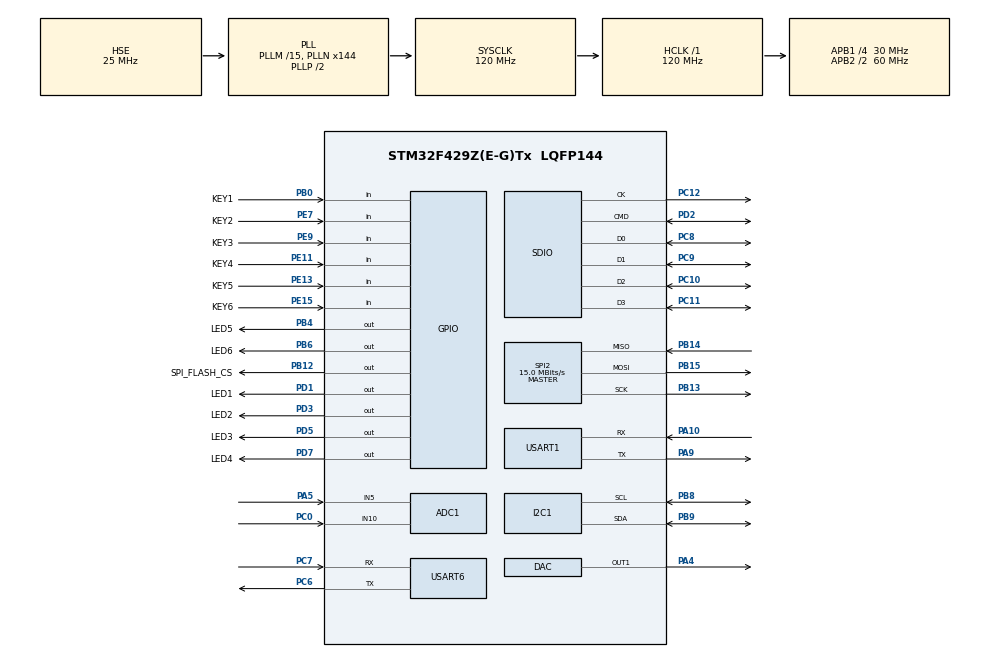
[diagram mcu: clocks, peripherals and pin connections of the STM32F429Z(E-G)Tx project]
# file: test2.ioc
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ADC1.Channel-0\#ChannelRegularConversion=ADC_CHANNEL_10
ADC1.Channel-1\#ChannelRegularConversion=ADC_CHANNEL_5
ADC1.ContinuousConvMode=DISABLE
ADC1.DMAContinuousRequests=DISABLE
ADC1.ExternalTrigConv=ADC_EXTERNALTRIGCONV_T3_TRGO
ADC1.NbrOfConversion=2
ADC1.NbrOfConversionFlag=1
ADC1.Rank-0\#ChannelRegularConversion=1
ADC1.Rank-1\#ChannelRegularConversion=2
ADC1.SamplingTime-0\#ChannelRegularConversion=ADC_SAMPLETIME_3CYCLES
ADC1.SamplingTime-1\#ChannelRegularConversion=ADC_SAMPLETIME_3CYCLES
ADC1.ScanConvMode=ENABLE
ADC1.master=1
DAC.DAC_Trigger=DAC_TRIGGER_T6_TRGO
Dma.ADC1.1.Direction=DMA_PERIPH_TO_MEMORY
Dma.ADC1.1.FIFOMode=DMA_FIFOMODE_DISABLE
Dma.ADC1.1.Instance=DMA2_Stream0
Dma.ADC1.1.MemDataAlignment=DMA_MDATAALIGN_WORD
Dma.ADC1.1.MemInc=DMA_MINC_ENABLE
Dma.ADC1.1.Mode=DMA_NORMAL
Dma.ADC1.1.PeriphDataAlignment=DMA_PDATAALIGN_WORD
Dma.ADC1.1.PeriphInc=DMA_PINC_DISABLE
Dma.ADC1.1.Priority=DMA_PRIORITY_LOW
Dma.DAC1.2.Direction=DMA_MEMORY_TO_PERIPH
Dma.DAC1.2.FIFOMode=DMA_FIFOMODE_DISABLE
Dma.DAC1.2.Instance=DMA1_Stream5
Dma.DAC1.2.MemDataAlignment=DMA_MDATAALIGN_HALFWORD
Dma.DAC1.2.MemInc=DMA_MINC_ENABLE
Dma.DAC1.2.Mode=DMA_CIRCULAR
Dma.DAC1.2.PeriphDataAlignment=DMA_PDATAALIGN_HALFWORD
Dma.DAC1.2.PeriphInc=DMA_PINC_DISABLE
Dma.DAC1.2.Priority=DMA_PRIORITY_LOW
Dma.Request0=USART1_RX
Dma.Request1=ADC1
Dma.Request2=DAC1
Dma.Request3=USART6_RX
Dma.USART1_RX.0.Direction=DMA_PERIPH_TO_MEMORY
Dma.USART1_RX.0.FIFOMode=DMA_FIFOMODE_DISABLE
Dma.USART1_RX.0.Instance=DMA2_Stream2
Dma.USART1_RX.0.MemDataAlignment=DMA_MDATAALIGN_BYTE
Dma.USART1_RX.0.MemInc=DMA_MINC_ENABLE
Dma.USART1_RX.0.Mode=DMA_NORMAL
Dma.USART1_RX.0.PeriphDataAlignment=DMA_PDATAALIGN_BYTE
Dma.USART1_RX.0.PeriphInc=DMA_PINC_DISABLE
Dma.USART1_RX.0.Priority=DMA_PRIORITY_HIGH
Dma.USART6_RX.3.Direction=DMA_PERIPH_TO_MEMORY
Dma.USART6_RX.3.FIFOMode=DMA_FIFOMODE_DISABLE
Dma.USART6_RX.3.Instance=DMA2_Stream1
Dma.USART6_RX.3.MemDataAlignment=DMA_MDATAALIGN_BYTE
Dma.USART6_RX.3.MemInc=DMA_MINC_ENABLE
Dma.USART6_RX.3.Mode=DMA_NORMAL
Dma.USART6_RX.3.PeriphDataAlignment=DMA_PDATAALIGN_BYTE
Dma.USART6_RX.3.PeriphInc=DMA_PINC_DISABLE
Dma.USART6_RX.3.Priority=DMA_PRIORITY_LOW
FATFS.USE_DMA_CODE_SD=0
FATFS._CODE_PAGE=936
FATFS._USE_LFN=3
I2C1.I2C_Mode=I2C_Fast
Mcu.Family=STM32F4
Mcu.Name=STM32F429Z(E-G)Tx
Mcu.Package=LQFP144
NVIC.ADC_IRQn=true\:0\:0\:true\:false\:true\:true\:true\:true
NVIC.DMA1_Stream5_IRQn=true\:0\:0\:true\:false\:true\:false\:true\:true
NVIC.DMA2_Stream0_IRQn=true\:0\:0\:true\:false\:true\:false\:true\:true
NVIC.DMA2_Stream1_IRQn=true\:0\:0\:false\:false\:true\:false\:true\:true
NVIC.DMA2_Stream2_IRQn=true\:0\:0\:false\:false\:true\:false\:true\:true
NVIC.PriorityGroup=NVIC_PRIORITYGROUP_2
NVIC.TIM8_UP_TIM13_IRQn=true\:0\:0\:false\:false\:true\:true\:true\:true
NVIC.USART1_IRQn=true\:0\:0\:false\:false\:true\:true\:true\:true
NVIC.USART6_IRQn=true\:0\:0\:false\:false\:true\:true\:true\:true
PA10.Mode=Asynchronous
PA10.Signal=USART1_RX
PA13.Mode=Serial_Wire
PA13.Signal=SYS_JTMS-SWDIO
PA14.Mode=Serial_Wire
PA14.Signal=SYS_JTCK-SWCLK
PA4.Signal=COMP_DAC1_group
PA5.Signal=ADCx_IN5
PA9.Mode=Asynchronous
PA9.Signal=USART1_TX
PB0.GPIO_Label=KEY1
PB0.GPIO_PuPd=GPIO_PULLUP
PB0.Signal=GPIO_Input
PB12.GPIO_Label=SPI_FLASH_CS
PB12.GPIO_Speed=GPIO_SPEED_FREQ_HIGH
PB12.PinState=GPIO_PIN_SET
PB12.Signal=GPIO_Output
PB13.Mode=Full_Duplex_Master
PB13.Signal=SPI2_SCK
PB14.Mode=Full_Duplex_Master
PB14.Signal=SPI2_MISO
PB15.Mode=Full_Duplex_Master
PB15.Signal=SPI2_MOSI
PB4.GPIO_Label=LED5
PB4.GPIO_PuPd=GPIO_PULLDOWN
PB4.Signal=GPIO_Output
PB6.GPIO_Label=LED6
PB6.GPIO_PuPd=GPIO_PULLDOWN
PB6.Signal=GPIO_Output
PB8.Mode=I2C
PB8.Signal=I2C1_SCL
PB9.Mode=I2C
PB9.Signal=I2C1_SDA
PC0.Signal=ADCx_IN10
PC10.Mode=SD_4_bits_Wide_bus
PC10.Signal=SDIO_D2
PC11.Mode=SD_4_bits_Wide_bus
PC11.Signal=SDIO_D3
PC12.Mode=SD_4_bits_Wide_bus
PC12.Signal=SDIO_CK
PC14/OSC32_IN.Mode=LSE-External-Oscillator
PC14/OSC32_IN.Signal=RCC_OSC32_IN
PC15/OSC32_OUT.Mode=LSE-External-Oscillator
PC15/OSC32_OUT.Signal=RCC_OSC32_OUT
PC6.Mode=Asynchronous
PC6.Signal=USART6_TX
PC7.Mode=Asynchronous
PC7.Signal=USART6_RX
PC8.Mode=SD_4_bits_Wide_bus
PC8.Signal=SDIO_D0
PC9.Mode=SD_4_bits_Wide_bus
PC9.Signal=SDIO_D1
PD1.GPIO_Label=LED1
PD1.GPIO_PuPd=GPIO_PULLDOWN
PD1.Signal=GPIO_Output
PD2.Mode=SD_4_bits_Wide_bus
PD2.Signal=SDIO_CMD
PD3.GPIO_Label=LED2
PD3.GPIO_PuPd=GPIO_PULLDOWN
PD3.Signal=GPIO_Output
PD5.GPIO_Label=LED3
PD5.GPIO_PuPd=GPIO_PULLDOWN
PD5.Signal=GPIO_Output
PD7.GPIO_Label=LED4
PD7.GPIO_PuPd=GPIO_PULLDOWN
PD7.Signal=GPIO_Output
PE11.GPIO_Label=KEY4
PE11.GPIO_PuPd=GPIO_PULLUP
PE11.Signal=GPIO_Input
PE13.GPIO_Label=KEY5
PE13.GPIO_PuPd=GPIO_PULLUP
PE13.Signal=GPIO_Input
PE15.GPIO_Label=KEY6
PE15.GPIO_PuPd=GPIO_PULLUP
PE15.Signal=GPIO_Input
PE7.GPIO_Label=KEY2
PE7.GPIO_PuPd=GPIO_PULLUP
PE7.Signal=GPIO_Input
PE9.GPIO_Label=KEY3
PE9.GPIO_PuPd=GPIO_PULLUP
PE9.Signal=GPIO_Input
PH0/OSC_IN.Mode=HSE-External-Oscillator
PH0/OSC_IN.Signal=RCC_OSC_IN
PH1/OSC_OUT.Mode=HSE-External-Oscillator
PH1/OSC_OUT.Signal=RCC_OSC_OUT
ProjectManager.HeapSize=0x200
ProjectManager.StackSize=0x400
ProjectManager.TargetToolchain=MDK-ARM V5.32
RCC.48MHZClocksFreq_Value=48000000
RCC.AHBFreq_Value=120000000
RCC.APB1CLKDivider=RCC_HCLK_DIV4
RCC.APB1Freq_Value=30000000
RCC.APB1TimFreq_Value=60000000
RCC.APB2CLKDivider=RCC_HCLK_DIV2
RCC.APB2Freq_Value=60000000
RCC.APB2TimFreq_Value=120000000
RCC.CortexFreq_Value=120000000
RCC.HCLKFreq_Value=120000000
RCC.HSE_VALUE=25000000
RCC.HSI_VALUE=16000000
RCC.PLLM=15
RCC.PLLN=144
RCC.PLLQ=5
RCC.PLLSourceVirtual=RCC_PLLSOURCE_HSE
RCC.SYSCLKFreq_VALUE=120000000
RCC.SYSCLKSource=RCC_SYSCLKSOURCE_PLLCLK
RCC.VCOOutputFreq_Value=240000000
SDIO.ClockDiv=6
SH.ADCx_IN10.0=ADC1_IN10,IN10
SH.ADCx_IN5.0=ADC1_IN5,IN5
SH.COMP_DAC1_group.0=DAC_OUT1,DAC_OUT1
SPI2.CLKPhase=SPI_PHASE_2EDGE
SPI2.CLKPolarity=SPI_POLARITY_HIGH
SPI2.CalculateBaudRate=15.0 MBits/s
SPI2.Direction=SPI_DIRECTION_2LINES
SPI2.Mode=SPI_MODE_MASTER
SPI2.VirtualType=VM_MASTER
STMicroelectronics.X-CUBE-ALGOBUILD.1.3.0.LibraryCcDSPOoLibraryJjDSPOoLibrary=true
TIM13.AutoReloadPreload=TIM_AUTORELOAD_PRELOAD_ENABLE
TIM13.Period=10000-1
TIM13.Prescaler=90-1
TIM3.AutoReloadPreload=TIM_AUTORELOAD_PRELOAD_ENABLE
TIM3.Period=100-1
TIM3.Prescaler=180-1
TIM3.TIM_MasterOutputTrigger=TIM_TRGO_UPDATE
TIM6.Period=100-1
TIM6.Prescaler=180-1
TIM6.TIM_MasterOutputTrigger=TIM_TRGO_UPDATE
USART1.VirtualMode=VM_ASYNC
USART6.VirtualMode=VM_ASYNC
VP_FATFS_VS_SDIO.Mode=SDIO
VP_STMicroelectronics.X-CUBE-ALGOBUILD_VS_DSPOoLibraryJjLibrary_1.3.0_1.3.0.Mode=DSPOoLibraryJjLibrary
VP_TIM13_VS_ClockSourceINT.Mode=Enable_Timer
VP_TIM3_VS_ClockSourceINT.Mode=Internal
VP_TIM6_VS_ClockSourceINT.Mode=Enable_Timer
board=custom

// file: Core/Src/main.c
/* USER CODE BEGIN Header */
/**
  ******************************************************************************
  * @file           : main.c
  * @brief          : Main program body
  ******************************************************************************
  * @attention
  *
  * Copyright (c) 2025 STMicroelectronics.
  * All rights reserved.
  *
  * This software is licensed under terms that can be found in the LICENSE file
  * in the root directory of this software component.
  * If no LICENSE file comes with this software, it is provided AS-IS.
  *
  ******************************************************************************
  */
/* USER CODE END Header */
#include "main.h"

void SystemClock_Config(void);

/* USER CODE BEGIN 0 */

/*=================================模块相关全局变量==========================*/

/* USER CODE END 0 */

int main(void)
{

  /* MCU Configuration--------------------------------------------------------*/

  /* Reset of all peripherals, Initializes the Flash interface and the Systick. */
  HAL_Init();

  /* Configure the system clock */
  SystemClock_Config();

  /* Initialize all configured peripherals */
  MX_GPIO_Init();
  MX_DMA_Init();
  MX_USART1_UART_Init();
  MX_ADC1_Init();
  MX_TIM3_Init();
  MX_DAC_Init();
  MX_TIM6_Init();
  MX_TIM13_Init();
  MX_I2C1_Init();
  MX_SPI2_Init();
  MX_SDIO_SD_Init();
  MX_FATFS_Init();
  MX_USART6_UART_Init();
  /* USER CODE BEGIN 2 */

/*===============================================各模块初始化===========================================*/

/*-------------------------------------基础外设初始化------------------------------------*/

	My_FFT_Init();		//初始化傅里叶变换
	app_ebtn_init();	//按键库初始化

	uart_init();		//串口三种模式可换
	websocket_init();

	app_dac_init();
	adc_init();			//ADC采样的三种模式

/*---------------------------OLED驱动 u8g2k库  WouoUI库  三选一-----------------------*/
	OLED_Init();		//初始化OLED
//	u8g2_init();		//初始化u8g2库
//	wououi_init();		//初始化wououi库

/*------------------------------SPI_flash的LittleFs库--------------------------------*/

/*=========1. 基于flash驱动库的简单读写==============*/
//	test_spi_flash();		//flash的读写测试

/*=========2. 基于flash LittleFs库的文件驱动简单示例=========*/

	lfs_init();			//初始化LittleFs库
	lfs_basic_test();

/*=========3.基于LittleFs文件驱动库的shell文件系统实例===========*/

	shell_init(&lfs); // 初始化Shell并传入文件系统实例

/*---------------------------------SD卡FATFS文件系统测试------------------------------------*/

	test_sd_fatfs();

/*-------------------------------------调度器初始化------------------------------------*/

	scheduler_init();	//调度器初始化

	my_printf(&huart1,"Init OK \r\n");

  /* USER CODE END 2 */

  /* Infinite loop */
  while (1)
  {

    /* USER CODE BEGIN 3 */

	  scheduler_run();

  }
  /* USER CODE END 3 */
}

void SystemClock_Config(void)
{
  RCC_OscInitTypeDef RCC_OscInitStruct = {0};
  RCC_ClkInitTypeDef RCC_ClkInitStruct = {0};

  /** Configure the main internal regulator output voltage
  */
  __HAL_RCC_PWR_CLK_ENABLE();
  __HAL_PWR_VOLTAGESCALING_CONFIG(PWR_REGULATOR_VOLTAGE_SCALE3);

  /** Initializes the RCC Oscillators according to the specified parameters
  * in the RCC_OscInitTypeDef structure.
  */
  RCC_OscInitStruct.OscillatorType = RCC_OSCILLATORTYPE_HSE;
  RCC_OscInitStruct.HSEState = RCC_HSE_ON;
  RCC_OscInitStruct.PLL.PLLState = RCC_PLL_ON;
  RCC_OscInitStruct.PLL.PLLSource = RCC_PLLSOURCE_HSE;
  RCC_OscInitStruct.PLL.PLLM = 15;
  RCC_OscInitStruct.PLL.PLLN = 144;
  RCC_OscInitStruct.PLL.PLLP = RCC_PLLP_DIV2;
  RCC_OscInitStruct.PLL.PLLQ = 5;
  if (HAL_RCC_OscConfig(&RCC_OscInitStruct) != HAL_OK)
  {
    Error_Handler();
  }

  /** Initializes the CPU, AHB and APB buses clocks
  */
  RCC_ClkInitStruct.ClockType = RCC_CLOCKTYPE_HCLK|RCC_CLOCKTYPE_SYSCLK
                              |RCC_CLOCKTYPE_PCLK1|RCC_CLOCKTYPE_PCLK2;
  RCC_ClkInitStruct.SYSCLKSource = RCC_SYSCLKSOURCE_PLLCLK;
  RCC_ClkInitStruct.AHBCLKDivider = RCC_SYSCLK_DIV1;
  RCC_ClkInitStruct.APB1CLKDivider = RCC_HCLK_DIV4;
  RCC_ClkInitStruct.APB2CLKDivider = RCC_HCLK_DIV2;

  if (HAL_RCC_ClockConfig(&RCC_ClkInitStruct, FLASH_LATENCY_3) != HAL_OK)
  {
    Error_Handler();
  }
}

void Error_Handler(void)
{
  __disable_irq();
  while (1)
  {
  }
}
